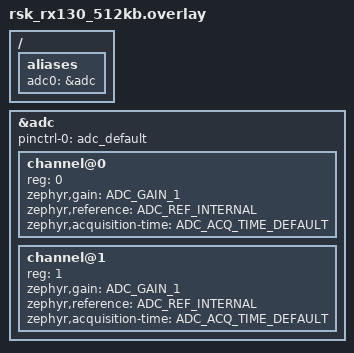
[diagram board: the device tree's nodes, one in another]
/*
 * Copyright (c) 2025 Renesas Electronics Corporation
 *
 * SPDX-License-Identifier: Apache-2.0
 */

/ {
	aliases {
		adc0 = &adc;
	};
};

&adc {
	pinctrl-0 = <&adc_default>;
	pinctrl-names = "default";
	#address-cells = <1>;
	#size-cells = <0>;
	status = "okay";

	channel@0 {
		reg = <0>;
		zephyr,gain = "ADC_GAIN_1";
		zephyr,reference = "ADC_REF_INTERNAL";
		zephyr,acquisition-time = <ADC_ACQ_TIME_DEFAULT>;
	};

	channel@1 {
		reg = <1>;
		zephyr,gain = "ADC_GAIN_1";
		zephyr,reference = "ADC_REF_INTERNAL";
		zephyr,acquisition-time = <ADC_ACQ_TIME_DEFAULT>;
	};
};
